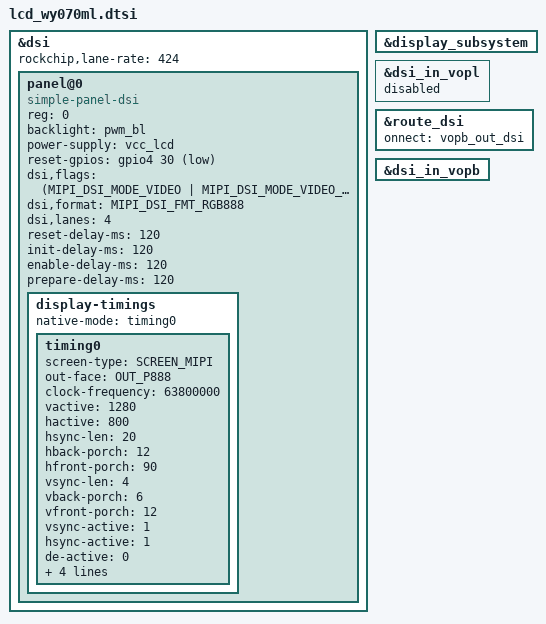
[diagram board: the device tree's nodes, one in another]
&dsi {
	status = "okay";
	rockchip,lane-rate = <424>;
	panel@0 {
		compatible ="simple-panel-dsi";
		reg = <0>;
		backlight = <&pwm_bl>;
		power-supply = <&vcc_lcd>;
		//enable-gpios = <&gpio1 13 GPIO_ACTIVE_HIGH>;
		reset-gpios = <&gpio4 30 GPIO_ACTIVE_LOW>;
		dsi,flags = <(MIPI_DSI_MODE_VIDEO | MIPI_DSI_MODE_VIDEO_BURST |
				MIPI_DSI_MODE_VIDEO_SYNC_PULSE)>;
		dsi,format = <MIPI_DSI_FMT_RGB888>;
		dsi,lanes = <4>;
		reset-delay-ms = <120>;
		init-delay-ms = <120>;
		enable-delay-ms = <120>;
		prepare-delay-ms = <120>;
		status = "okay";
//		panel-exit-sequence = [
//			05 00 01 28
//			05 00 01 10
//		];

		display-timings{
			native-mode = <&timing0>;
			timing0: timing0 {
				screen-type = <SCREEN_MIPI>;
				out-face    = <OUT_P888>;
				clock-frequency = <63800000>;
				vactive = <1280>;
				hactive = <800>;
				hsync-len = <20>;      //14//20
				hback-porch = <12>;    //12//4
				hfront-porch = <90>;  //268//290
			
				vsync-len = <4>;    //2//4
				vback-porch = <6>;  //2//4
				vfront-porch = <12>; //4
			
				vsync-active = <1>;
				hsync-active = <1>;
				de-active = <0>;
				pixelclk-active = <1>;
				swap-rb = <0>;
				swap-rg = <0>;
				swap-gb = <0>;
			};
		};

	};
};

&display_subsystem{
	status = "okay";

};

&dsi_in_vopl {
	status = "disabled";
};

&route_dsi {
	status = "okay";
	onnect = <&vopb_out_dsi>;
};

&dsi_in_vopb {
	status = "okay";
};
